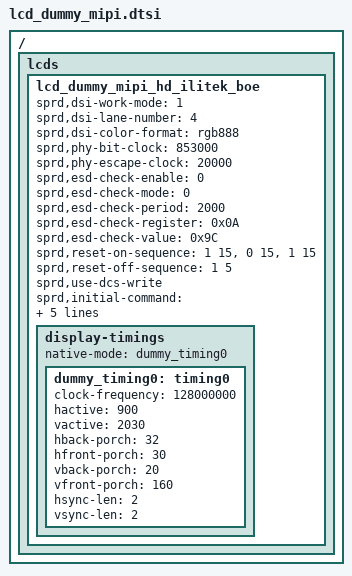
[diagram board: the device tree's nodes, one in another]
// SPDX-License-Identifier: GPL-2.0-only
/*
 * Unisoc Dummy LCD config DTS file
 *
 * Copyright (C) 2021, Unisoc Inc.
 */
/ {
	fragment {
		target-path = "/";
		__overlay__ {
			lcds {
				lcd_dummy_mipi_hd_ilitek_boe: lcd_dummy_mipi_hd_ilitek_boe {

					sprd,dsi-work-mode = <1>; /* video burst mode*/
					sprd,dsi-lane-number = <4>;
					sprd,dsi-color-format = "rgb888";

					sprd,phy-bit-clock = <853000>;  /* kbps */
					sprd,phy-escape-clock = <20000>;/* kHz */
					/*sprd,width-mm = <69>;
					sprd,height-mm = <157>;*/
					sprd,esd-check-enable = <0>;
					sprd,esd-check-mode = <0>;  // 0:Reg mode 1:TE mode
					sprd,esd-check-period = <2000>;
					sprd,esd-check-register = <0x0A>;
					sprd,esd-check-value = <0x9C>;
					sprd,reset-on-sequence = <1 15>, <0 15>, <1 15>;
					sprd,reset-off-sequence = <1 5>;
					sprd,use-dcs-write;
					sprd,initial-command = [
						39 00 00 04 FF 5A A5 01
						23 00 00 02 00 53
						23 00 00 02 01 17
						23 00 00 02 02 00
						23 00 00 02 03 00
						23 00 00 02 04 CF
						23 00 00 02 05 17
						23 00 00 02 06 00
						23 00 00 02 07 00


						23 00 00 02 08 8D
						23 00 00 02 09 02
						23 00 00 02 0A F6
						23 00 00 02 0B 00
						23 00 00 02 0C 00
						23 00 00 02 0D 00
						23 00 00 02 0E 00
						23 00 00 02 0F 00
						23 00 00 02 10 10
						23 00 00 02 16 8D
						23 00 00 02 17 02
						23 00 00 02 18 76
						23 00 00 02 19 00
						23 00 00 02 1A 00
						23 00 00 02 1B 00
						23 00 00 02 1C 00
						23 00 00 02 1D 00
						23 00 00 02 1E 10


						23 00 00 02 28 8A
						23 00 00 02 29 55
						23 00 00 02 2A 8A
						23 00 00 02 2B 55
						23 00 00 02 92 8A
						23 00 00 02 93 54
						23 00 00 02 98 60
						23 00 00 02 EE 10
						23 00 00 02 EF 00
						23 00 00 02 F0 00


						23 00 00 02 31 00
						23 00 00 02 32 22
						23 00 00 02 33 2A
						23 00 00 02 34 19
						23 00 00 02 35 1B
						23 00 00 02 36 1D
						23 00 00 02 37 1F
						23 00 00 02 38 11
						23 00 00 02 39 13
						23 00 00 02 3A 15
						23 00 00 02 3B 17
						23 00 00 02 3C 23
						23 00 00 02 3D 09
						23 00 00 02 3E 0D
						23 00 00 02 3F 07
						23 00 00 02 40 07
						23 00 00 02 41 07
						23 00 00 02 42 07
						23 00 00 02 43 07
						23 00 00 02 44 07
						23 00 00 02 45 07
						23 00 00 02 46 07

						23 00 00 02 47 00
						23 00 00 02 48 22
						23 00 00 02 49 2A
						23 00 00 02 4A 18
						23 00 00 02 4B 1A
						23 00 00 02 4C 1C
						23 00 00 02 4D 1E
						23 00 00 02 4E 10
						23 00 00 02 4F 12
						23 00 00 02 50 14
						23 00 00 02 51 16
						23 00 00 02 52 23
						23 00 00 02 53 08
						23 00 00 02 54 0C
						23 00 00 02 55 07
						23 00 00 02 56 07
						23 00 00 02 57 07
						23 00 00 02 58 07
						23 00 00 02 59 07
						23 00 00 02 5A 07
						23 00 00 02 5B 07
						23 00 00 02 5C 07

						23 00 00 02 61 2D
						23 00 00 02 62 22
						23 00 00 02 63 2A
						23 00 00 02 64 16
						23 00 00 02 65 14
						23 00 00 02 66 12
						23 00 00 02 67 10
						23 00 00 02 68 1E
						23 00 00 02 69 1C
						23 00 00 02 6A 1A
						23 00 00 02 6B 18
						23 00 00 02 6C 23
						23 00 00 02 6D 0C
						23 00 00 02 6E 08
						23 00 00 02 6F 07
						23 00 00 02 70 07
						23 00 00 02 71 07
						23 00 00 02 72 07
						23 00 00 02 73 07
						23 00 00 02 74 07
						23 00 00 02 75 07
						23 00 00 02 76 07

						23 00 00 02 77 2D
						23 00 00 02 78 22
						23 00 00 02 79 2A
						23 00 00 02 7A 17
						23 00 00 02 7B 15
						23 00 00 02 7C 13
						23 00 00 02 7D 11
						23 00 00 02 7E 1F
						23 00 00 02 7F 1D
						23 00 00 02 80 1B
						23 00 00 02 81 19
						23 00 00 02 82 23
						23 00 00 02 83 0D
						23 00 00 02 84 09
						23 00 00 02 85 07
						23 00 00 02 86 07
						23 00 00 02 87 07
						23 00 00 02 88 07
						23 00 00 02 89 07
						23 00 00 02 8A 07
						23 00 00 02 8B 07
						23 00 00 02 8C 07


						23 00 00 02 D1 10
						23 00 00 02 D3 10
						23 00 00 02 D5 00
						23 00 00 02 D8 00
						23 00 00 02 DA 00
						23 00 00 02 DC B7
						23 00 00 02 DD 08
						23 00 00 02 99 40
						23 00 00 02 E0 5E
						23 00 00 02 E2 72
						23 00 00 02 E3 01
						23 00 00 02 E6 22
						23 00 00 02 C1 00
						23 00 00 02 C3 00
						23 00 00 02 F8 08

						39 00 00 04 FF 5A A5 02
						23 00 00 02 1B A0
						23 00 00 02 40 06
						23 00 00 02 43 1A
						23 00 00 02 4D 8E
						23 00 00 02 51 20
						23 00 00 02 6B 33


						39 00 00 04 FF 5A A5 12
						23 00 00 02 07 00
						23 00 00 02 08 F1
						23 00 00 02 18 00
						23 00 00 02 19 E2
						23 00 00 02 1A 00
						23 00 00 02 1B 16
						23 00 00 02 1C 00
						23 00 00 02 1D A0


						39 00 00 04 FF 5A A5 03
						23 00 00 02 59 03
						23 00 00 02 5A 84
						23 00 00 02 5B 07
						23 00 00 02 5C EE


						39 00 00 04 FF 5A A5 14
						23 00 00 02 86 00
						23 00 00 02 87 EC

						39 00 00 04 FF 5A A5 05
						23 00 00 02 55 61
						23 00 00 02 56 57
						23 00 00 02 5A B5
						23 00 00 02 60 BB
						23 00 00 02 66 A1
						23 00 00 02 6C 93
						23 00 00 02 54 87
						23 00 00 02 1E 0B
						23 00 00 02 53 0A
						23 00 00 02 44 4A


						39 00 00 04 FF 5A A5 06
						23 00 00 02 D9 1F
						23 00 00 02 C0 EE
						23 00 00 02 C1 07
						23 00 00 02 CA 84
						23 00 00 02 CB 03

						39 00 00 04 FF 5A A5 07
						23 00 00 02 35 80


						39 00 00 04 FF 5A A5 08
						39 00 00 1E E0 00 00 10 39 63 40 9E D3 FB 2E 95 57 9C D3 04 AA 34 64 9C C0 FE EA 0D 3B 72 3F 9F D0 DA
						39 00 00 1E E1 00 00 10 39 63 40 9E D3 FB 2E 95 57 9C D3 04 AA 34 64 9C C0 FE EA 0D 3B 72 3F 9F D0 DA


						39 00 00 04 FF 5A A5 0B
						23 00 00 02 A0 87
						23 00 00 02 A1 87
						23 00 00 02 A2 05
						23 00 00 02 A3 05
						23 00 00 02 A4 BC
						23 00 00 02 A5 BC
						23 00 00 02 BC 22
						23 00 00 02 BD E0


						39 00 00 04 FF 5A A5 0E
						23 00 00 02 1A 0A
						23 00 00 02 12 02
						23 00 00 02 7D 0A
						23 00 00 02 00 80

						39 00 00 04 FF 5A A5 00
						23 00 00 02 35 00
						23 78 00 02 11 00
						23 14 00 02 29 00
						];
					sprd,sleep-in-command = [
						13 0A 00 01 28
						13 78 00 01 10
						];
					sprd,sleep-out-command = [
						13 78 00 01 11
						13 64 00 01 29
						];

					display-timings {
						native-mode = <&dummy_timing0>;

						dummy_timing0: timing0 {
							clock-frequency = <128000000>;
							hactive = <900>;
							vactive = <2030>;
							hback-porch = <32>;
							hfront-porch = <30>;
							vback-porch = <20>;
							vfront-porch = <160>;
							hsync-len = <2>;
							vsync-len = <2>;
						};
					};
				};
			};
		};
	};
};
